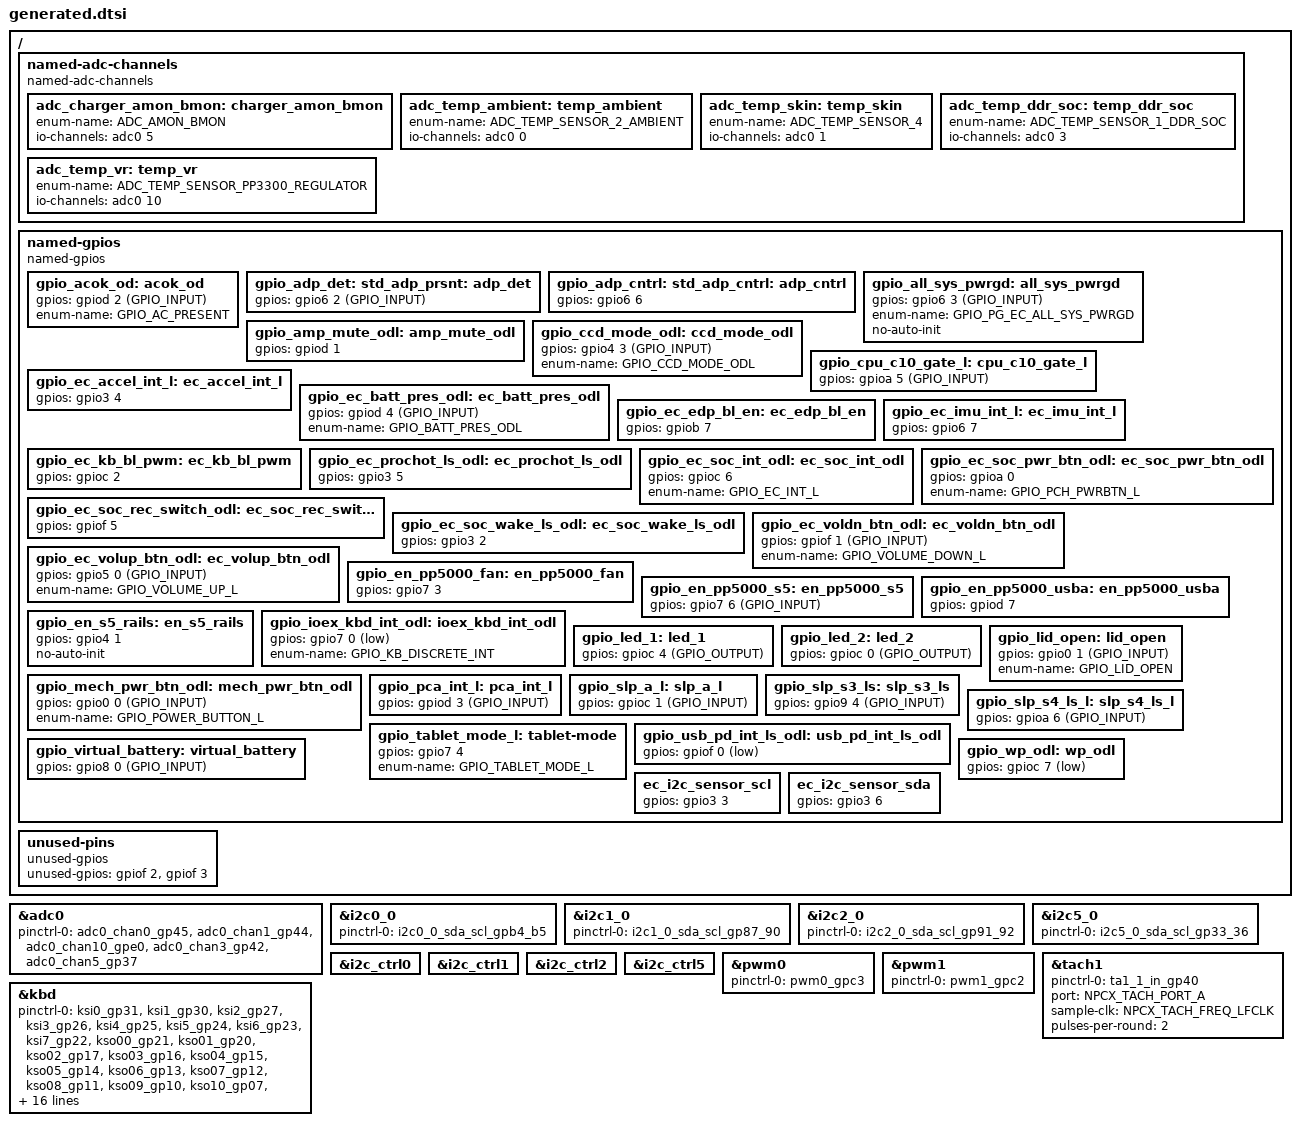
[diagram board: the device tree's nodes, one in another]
/* Copyright 2025 The ChromiumOS Authors
 * Use of this source code is governed by a BSD-style license that can be
 * found in the LICENSE file.
 *
 * This file was auto-generated but contains manual edits
 */

/ {

	named-adc-channels {
		compatible = "named-adc-channels";

		adc_charger_amon_bmon: charger_amon_bmon {
			enum-name = "ADC_AMON_BMON";
			io-channels = <&adc0 5>;
		};
		adc_temp_ambient: temp_ambient {
			enum-name = "ADC_TEMP_SENSOR_2_AMBIENT";
			io-channels = <&adc0 0>;
		};
		adc_temp_skin: temp_skin {
			enum-name = "ADC_TEMP_SENSOR_4";
			io-channels = <&adc0 1>;
		};
		adc_temp_vr: temp_vr {
			enum-name = "ADC_TEMP_SENSOR_PP3300_REGULATOR";
			io-channels = <&adc0 10>;
		};
		adc_temp_ddr_soc: temp_ddr_soc {
			enum-name = "ADC_TEMP_SENSOR_1_DDR_SOC";
			io-channels = <&adc0 3>;
		};
	};

	named-gpios {
		compatible = "named-gpios";

		gpio_acok_od: acok_od {
			gpios = <&gpiod 2 (GPIO_INPUT)>;
			enum-name = "GPIO_AC_PRESENT";
		};
		gpio_adp_det: std_adp_prsnt: adp_det {
			gpios = <&gpio6 2 (GPIO_INPUT)>;
		};
		gpio_adp_cntrl: std_adp_cntrl: adp_cntrl {
			gpios = <&gpio6 6 (GPIO_OUTPUT | GPIO_ACTIVE_HIGH)>;
		};
		/* Power sequencing signal needed by fan driver */
		gpio_all_sys_pwrgd: all_sys_pwrgd {
			gpios = <&gpio6 3 (GPIO_INPUT)>;
			enum-name = "GPIO_PG_EC_ALL_SYS_PWRGD";
			no-auto-init;
		};
		gpio_amp_mute_odl: amp_mute_odl {
			gpios = <&gpiod 1 (GPIO_OUTPUT | GPIO_OPEN_DRAIN | GPIO_ACTIVE_HIGH |
						GPIO_OUTPUT_INIT_HIGH | GPIO_OUTPUT_INIT_LOGICAL |
						GPIO_VOLTAGE_1P8)>;
		};
		gpio_ccd_mode_odl: ccd_mode_odl {
			gpios = <&gpio4 3 (GPIO_INPUT)>;
			enum-name = "GPIO_CCD_MODE_ODL";
		};
		gpio_cpu_c10_gate_l: cpu_c10_gate_l {
			gpios = <&gpioa 5 (GPIO_INPUT)>;
		};
		gpio_ec_accel_int_l: ec_accel_int_l {
			gpios = <&gpio3 4 (GPIO_INPUT | GPIO_VOLTAGE_1P8)>;
		};
		gpio_ec_batt_pres_odl: ec_batt_pres_odl {
			gpios = <&gpiod 4 (GPIO_INPUT)>;
			enum-name = "GPIO_BATT_PRES_ODL";
		};
		gpio_ec_edp_bl_en: ec_edp_bl_en {
			gpios = <&gpiob 7 (GPIO_OUTPUT | GPIO_ACTIVE_HIGH | GPIO_OUTPUT_INIT_HIGH |
						GPIO_OUTPUT_INIT_LOGICAL)>;
		};
		gpio_ec_imu_int_l: ec_imu_int_l {
			gpios = <&gpio6 7 (GPIO_INPUT | GPIO_VOLTAGE_1P8)>;
		};
		gpio_ec_kb_bl_pwm: ec_kb_bl_pwm {
			gpios = <&gpioc 2 (GPIO_OUTPUT | GPIO_ACTIVE_HIGH)>;
		};
		gpio_ec_prochot_ls_odl: ec_prochot_ls_odl {
			gpios = <&gpio3 5 (GPIO_OUTPUT | GPIO_OPEN_DRAIN | GPIO_ACTIVE_HIGH | GPIO_OUTPUT_INIT_HIGH)>;
		};
		gpio_ec_soc_int_odl: ec_soc_int_odl {
			gpios = <&gpioc 6 (GPIO_OUTPUT | GPIO_OPEN_DRAIN | GPIO_ACTIVE_HIGH | GPIO_OUTPUT_INIT_HIGH | GPIO_VOLTAGE_1P8)>;
			enum-name = "GPIO_EC_INT_L";
		};
		gpio_ec_soc_pwr_btn_odl: ec_soc_pwr_btn_odl {
			gpios = <&gpioa 0 (GPIO_OUTPUT | GPIO_OPEN_DRAIN | GPIO_ACTIVE_HIGH | GPIO_OUTPUT_INIT_HIGH)>;
			enum-name = "GPIO_PCH_PWRBTN_L";
		};
		gpio_ec_soc_rec_switch_odl: ec_soc_rec_switch_odl {
			gpios = <&gpiof 5 (GPIO_OUTPUT | GPIO_OPEN_DRAIN | GPIO_ACTIVE_HIGH | GPIO_OUTPUT_INIT_LOW | GPIO_VOLTAGE_1P8)>;
		};
		gpio_ec_soc_wake_ls_odl: ec_soc_wake_ls_odl {
			gpios = <&gpio3 2 (GPIO_OUTPUT | GPIO_OPEN_DRAIN | GPIO_ACTIVE_HIGH | GPIO_OUTPUT_INIT_LOW)>;
		};
		gpio_ec_voldn_btn_odl: ec_voldn_btn_odl {
			gpios = <&gpiof 1 (GPIO_INPUT)>;
			enum-name = "GPIO_VOLUME_DOWN_L";
		};
		gpio_ec_volup_btn_odl: ec_volup_btn_odl {
			gpios = <&gpio5 0 (GPIO_INPUT)>;
			enum-name = "GPIO_VOLUME_UP_L";
		};
		gpio_en_pp5000_fan: en_pp5000_fan {
			gpios = <&gpio7 3 (GPIO_OUTPUT | GPIO_ACTIVE_HIGH | GPIO_OUTPUT_INIT_LOW)>;
		};
		gpio_en_pp5000_s5: en_pp5000_s5 {
			gpios = <&gpio7 6 (GPIO_INPUT)>;
		};
		gpio_en_pp5000_usba: en_pp5000_usba {
			gpios = <&gpiod 7 (GPIO_OUTPUT | GPIO_ACTIVE_HIGH)>;
		};
		/* Power sequencing signal needed by temp sensor driver */
		gpio_en_s5_rails: en_s5_rails {
			gpios = <&gpio4 1 (GPIO_OUTPUT | GPIO_ACTIVE_HIGH | GPIO_OUTPUT_INIT_LOW)>;
			no-auto-init;
		};
		gpio_ioex_kbd_int_odl: ioex_kbd_int_odl {
			gpios = <&gpio7 0 (GPIO_INPUT | GPIO_ACTIVE_LOW)>;
			enum-name = "GPIO_KB_DISCRETE_INT";
		};
		gpio_led_1: led_1 {
			gpios = <&gpioc 4 (GPIO_OUTPUT)>;
		};
		gpio_led_2: led_2 {
			gpios = <&gpioc 0 (GPIO_OUTPUT)>;
		};
		gpio_lid_open: lid_open {
			gpios = <&gpio0 1 (GPIO_INPUT)>;
			enum-name = "GPIO_LID_OPEN";
		};
		gpio_mech_pwr_btn_odl: mech_pwr_btn_odl {
			// signal name was manually overriden from "ec_mech_pwr_btn_l"
			gpios = <&gpio0 0 (GPIO_INPUT)>;
			enum-name = "GPIO_POWER_BUTTON_L";
		};
		gpio_pca_int_l: pca_int_l {
			gpios = <&gpiod 3 (GPIO_INPUT)>;
		};
		gpio_slp_a_l: slp_a_l {
			gpios = <&gpioc 1 (GPIO_INPUT)>;
		};
		gpio_slp_s3_ls: slp_s3_ls {
			gpios = <&gpio9 4 (GPIO_INPUT)>;
		};
		gpio_slp_s4_ls_l: slp_s4_ls_l {
			gpios = <&gpioa 6 (GPIO_INPUT)>;
		};
		gpio_tablet_mode_l: tablet-mode {
			gpios = <&gpio7 4 (GPIO_INPUT | GPIO_VOLTAGE_1P8)>;
			enum-name = "GPIO_TABLET_MODE_L";
		};
		gpio_usb_pd_int_ls_odl: usb_pd_int_ls_odl {
			gpios = <&gpiof 0 (GPIO_INPUT | GPIO_ACTIVE_LOW)>;
		};
		gpio_virtual_battery: virtual_battery {
			gpios = <&gpio8 0 (GPIO_INPUT)>;
		};
		gpio_wp_odl: wp_odl {
			// signal name was manually overriden from "ec_soc_rtcrst_odl"
			gpios = <&gpioc 7 (GPIO_INPUT | GPIO_ACTIVE_LOW)>;
		};

		/* Set ISH/sensor I2C bus (i2c5_0) voltage thresholds to 1.8V.
		 * These are not actually GPIOs and will be taken over by the
		 * I2C controller. */
		ec_i2c_sensor_scl {
			gpios = <&gpio3 3 (GPIO_INPUT | GPIO_VOLTAGE_1P8)>;
		};
		ec_i2c_sensor_sda {
			gpios = <&gpio3 6 (GPIO_INPUT | GPIO_VOLTAGE_1P8)>;
		};
	};

	unused-pins {
		compatible = "unused-gpios";
		unused-gpios =
			/* BGA_PINF6 - unused 1.8V I2C bus - pull down to avoid
			 * voltage level issues if this AIC is connected to a
			 * different base RVP board */
			<&gpiof 2 (GPIO_INPUT | GPIO_PULL_DOWN)>,
			/* BGA_PINF5 - unused 1.8V I2C bus - pull down to avoid
			 * voltage level issues if this AIC is connected to a
			 * different base RVP board */
			<&gpiof 3 (GPIO_INPUT | GPIO_PULL_DOWN)>;
	};
};

&adc0 {
	status = "okay";
	pinctrl-0 = <&adc0_chan0_gp45
		&adc0_chan1_gp44
		&adc0_chan10_gpe0
		&adc0_chan3_gp42
		&adc0_chan5_gp37>;
	pinctrl-names = "default";
};

&i2c0_0 {
	status = "okay";
	pinctrl-0 = <&i2c0_0_sda_scl_gpb4_b5>;
	pinctrl-names = "default";
};

&i2c1_0 {
	status = "okay";
	pinctrl-0 = <&i2c1_0_sda_scl_gp87_90>;
	pinctrl-names = "default";
};

&i2c2_0 {
	status = "okay";
	pinctrl-0 = <&i2c2_0_sda_scl_gp91_92>;
	pinctrl-names = "default";
};

&i2c5_0 {
	status = "okay";
	pinctrl-0 = <&i2c5_0_sda_scl_gp33_36>;
	pinctrl-names = "default";
};

&i2c_ctrl0 {
	status = "okay";
};

&i2c_ctrl1 {
	status = "okay";
};

&i2c_ctrl2 {
	status = "okay";
};

&i2c_ctrl5 {
	status = "okay";
};

&pwm0 {
	status = "okay";
	pinctrl-0 = <&pwm0_gpc3>;
	pinctrl-names = "default";
};

&pwm1 {
	status = "okay";
	pinctrl-0 = <&pwm1_gpc2>;
	pinctrl-names = "default";
};

&tach1 {
	status = "okay";
	pinctrl-0 = <&ta1_1_in_gp40>;
	pinctrl-names = "default";
	port = <NPCX_TACH_PORT_A>;
	sample-clk = <NPCX_TACH_FREQ_LFCLK>;
	pulses-per-round = <2>;
};

&kbd {
	status = "okay";
	pinctrl-0 = <
		&ksi0_gp31
		&ksi1_gp30
		&ksi2_gp27
		&ksi3_gp26
		&ksi4_gp25
		&ksi5_gp24
		&ksi6_gp23
		&ksi7_gp22
		&kso00_gp21
		&kso01_gp20
		&kso02_gp17
		&kso03_gp16
		&kso04_gp15
		&kso05_gp14
		&kso06_gp13
		&kso07_gp12
		&kso08_gp11
		&kso09_gp10
		&kso10_gp07
		&kso11_gp06
		&kso12_gp05
		&kso13_gp04
		&kso14_gp82
		&kso15_gp83
		&kso16_gp03
		&kso17_gpb1
	>;
	pinctrl-1 = <
		&ksi0_gpio_gp31
		&ksi1_gpio_gp30
		&ksi2_gpio_gp27
		&ksi3_gpio_gp26
		&ksi4_gpio_gp25
		&ksi5_gpio_gp24
		&ksi6_gpio_gp23
		&ksi7_gpio_gp22
		&kso00_gpio_gp21
		&kso01_gpio_gp20
		&kso02_gpio_gp17
		&kso03_gpio_gp16
		&kso04_gpio_gp15
		&kso05_gpio_gp14
		&kso06_gpio_gp13
		&kso07_gpio_gp12
		&kso08_gpio_gp11
		&kso09_gpio_gp10
		&kso10_gpio_gp07
		&kso11_gpio_gp06
		&kso12_gpio_gp05
		&kso13_gpio_gp04
		&kso14_gpio_gp82
		&kso15_gpio_gp83
		&kso16_gpio_gp03
		&kso17_gpio_gpb1
	>;
	pinctrl-names = "default", "sleep";
};
